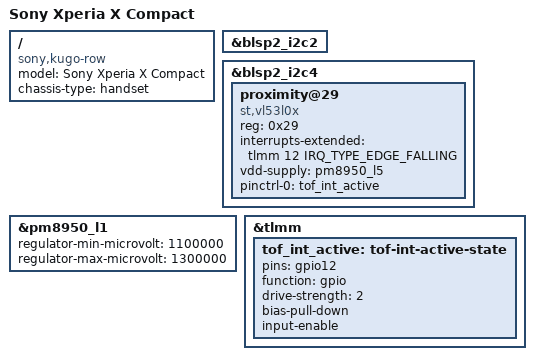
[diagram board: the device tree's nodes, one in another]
// SPDX-License-Identifier: BSD-3-Clause
/*
 * Copyright (c) 2016-2022, AngeloGioacchino Del Regno
 *                          <angelogioacchino.delregno@somainline.org>
 * Copyright (c) 2022, Konrad Dybcio <konrad.dybcio@somainline.org>
 * Copyright (c) 2022, Marijn Suijten <marijn.suijten@somainline.org>
 */

/dts-v1/;

#include "msm8956-sony-xperia-loire.dtsi"

/ {
	model = "Sony Xperia X Compact";
	compatible = "sony,kugo-row", "qcom,msm8956";
	chassis-type = "handset";
};

&blsp2_i2c2 {
	status = "okay";

	/* FUSB301 USB-C Controller */
};

&blsp2_i2c4 {
	status = "okay";

	/* AMS TCS349 RGBCIR @ 72 */

	proximity@29 {
		compatible = "st,vl53l0x";
		reg = <0x29>;
		interrupts-extended = <&tlmm 12 IRQ_TYPE_EDGE_FALLING>;
		vdd-supply = <&pm8950_l5>;

		pinctrl-names = "default";
		pinctrl-0 = <&tof_int_active>;
	};
};

&pm8950_l1 {
	regulator-min-microvolt = <1100000>;
	regulator-max-microvolt = <1300000>;
};

&tlmm {
	tof_int_active: tof-int-active-state {
		pins = "gpio12";
		function = "gpio";
		drive-strength = <2>;
		bias-pull-down;
		input-enable;
	};
};
